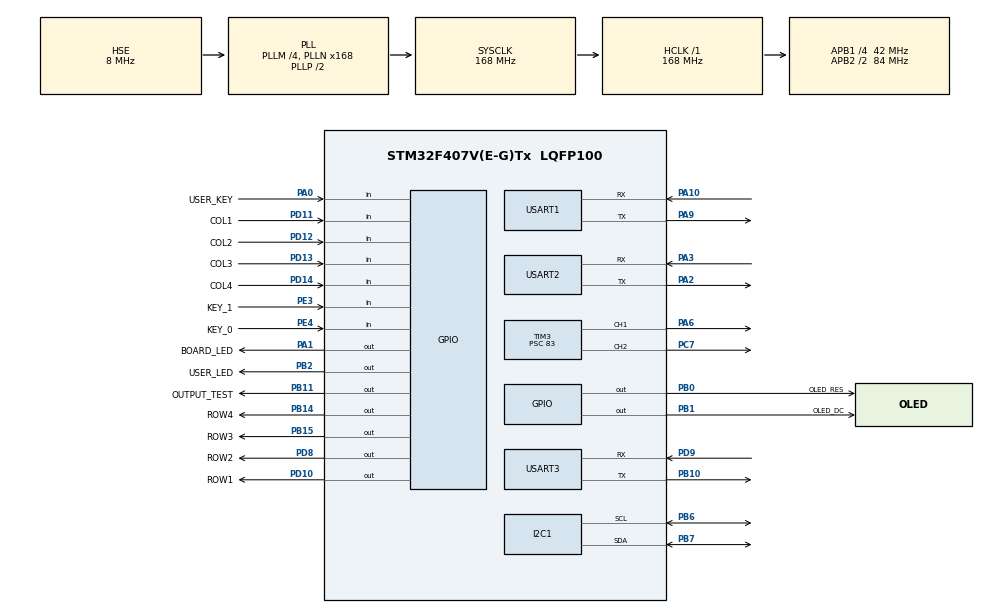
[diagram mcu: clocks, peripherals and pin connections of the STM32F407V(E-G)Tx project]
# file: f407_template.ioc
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Dma.Request0=USART2_RX
Dma.Request1=USART2_TX
Dma.Request2=USART1_RX
Dma.Request3=USART1_TX
Dma.USART1_RX.2.Direction=DMA_PERIPH_TO_MEMORY
Dma.USART1_RX.2.FIFOMode=DMA_FIFOMODE_DISABLE
Dma.USART1_RX.2.Instance=DMA2_Stream2
Dma.USART1_RX.2.MemDataAlignment=DMA_MDATAALIGN_BYTE
Dma.USART1_RX.2.MemInc=DMA_MINC_ENABLE
Dma.USART1_RX.2.Mode=DMA_NORMAL
Dma.USART1_RX.2.PeriphDataAlignment=DMA_PDATAALIGN_BYTE
Dma.USART1_RX.2.PeriphInc=DMA_PINC_DISABLE
Dma.USART1_RX.2.Priority=DMA_PRIORITY_LOW
Dma.USART1_TX.3.Direction=DMA_MEMORY_TO_PERIPH
Dma.USART1_TX.3.FIFOMode=DMA_FIFOMODE_DISABLE
Dma.USART1_TX.3.Instance=DMA2_Stream7
Dma.USART1_TX.3.MemDataAlignment=DMA_MDATAALIGN_BYTE
Dma.USART1_TX.3.MemInc=DMA_MINC_ENABLE
Dma.USART1_TX.3.Mode=DMA_NORMAL
Dma.USART1_TX.3.PeriphDataAlignment=DMA_PDATAALIGN_BYTE
Dma.USART1_TX.3.PeriphInc=DMA_PINC_DISABLE
Dma.USART1_TX.3.Priority=DMA_PRIORITY_LOW
Dma.USART2_RX.0.Direction=DMA_PERIPH_TO_MEMORY
Dma.USART2_RX.0.FIFOMode=DMA_FIFOMODE_DISABLE
Dma.USART2_RX.0.Instance=DMA1_Stream5
Dma.USART2_RX.0.MemDataAlignment=DMA_MDATAALIGN_BYTE
Dma.USART2_RX.0.MemInc=DMA_MINC_ENABLE
Dma.USART2_RX.0.Mode=DMA_NORMAL
Dma.USART2_RX.0.PeriphDataAlignment=DMA_PDATAALIGN_BYTE
Dma.USART2_RX.0.PeriphInc=DMA_PINC_DISABLE
Dma.USART2_RX.0.Priority=DMA_PRIORITY_MEDIUM
Dma.USART2_TX.1.Direction=DMA_MEMORY_TO_PERIPH
Dma.USART2_TX.1.FIFOMode=DMA_FIFOMODE_DISABLE
Dma.USART2_TX.1.Instance=DMA1_Stream6
Dma.USART2_TX.1.MemDataAlignment=DMA_MDATAALIGN_BYTE
Dma.USART2_TX.1.MemInc=DMA_MINC_ENABLE
Dma.USART2_TX.1.Mode=DMA_NORMAL
Dma.USART2_TX.1.PeriphDataAlignment=DMA_PDATAALIGN_BYTE
Dma.USART2_TX.1.PeriphInc=DMA_PINC_DISABLE
Dma.USART2_TX.1.Priority=DMA_PRIORITY_MEDIUM
I2C1.I2C_Mode=I2C_Standard
Mcu.Family=STM32F4
Mcu.Name=STM32F407V(E-G)Tx
Mcu.Package=LQFP100
NVIC.DMA1_Stream5_IRQn=true\:0\:0\:false\:false\:true\:false\:true\:true
NVIC.DMA1_Stream6_IRQn=true\:0\:0\:false\:false\:true\:false\:true\:true
NVIC.DMA2_Stream2_IRQn=true\:0\:0\:false\:false\:true\:false\:true\:true
NVIC.DMA2_Stream7_IRQn=true\:0\:0\:false\:false\:true\:false\:true\:true
NVIC.PriorityGroup=NVIC_PRIORITYGROUP_4
NVIC.TIM6_DAC_IRQn=true\:0\:0\:false\:false\:true\:true\:true\:true
NVIC.USART1_IRQn=true\:0\:0\:false\:false\:true\:true\:true\:true
NVIC.USART2_IRQn=true\:0\:0\:false\:false\:true\:true\:true\:true
PA0-WKUP.GPIO_Label=USER_KEY
PA0-WKUP.GPIO_PuPd=GPIO_PULLDOWN
PA0-WKUP.Signal=GPIO_Input
PA1.GPIO_Label=BOARD_LED
PA1.PinState=GPIO_PIN_RESET
PA1.Signal=GPIO_Output
PA10.Mode=Asynchronous
PA10.Signal=USART1_RX
PA13.Mode=Serial_Wire
PA13.Signal=SYS_JTMS-SWDIO
PA14.Mode=Serial_Wire
PA14.Signal=SYS_JTCK-SWCLK
PA2.Mode=Asynchronous
PA2.Signal=USART2_TX
PA3.Mode=Asynchronous
PA3.Signal=USART2_RX
PA6.Signal=S_TIM3_CH1
PA9.Mode=Asynchronous
PA9.Signal=USART1_TX
PB0.GPIO_Label=OLED_RES
PB0.Signal=GPIO_Output
PB1.GPIO_Label=OLED_DC
PB1.Signal=GPIO_Output
PB10.Mode=Asynchronous
PB10.Signal=USART3_TX
PB11.GPIO_Label=OUTPUT_TEST
PB11.GPIO_Speed=GPIO_SPEED_FREQ_HIGH
PB11.Signal=GPIO_Output
PB14.GPIO_Label=ROW4
PB14.GPIO_Speed=GPIO_SPEED_FREQ_HIGH
PB14.PinState=GPIO_PIN_SET
PB14.Signal=GPIO_Output
PB15.GPIO_Label=ROW3
PB15.GPIO_Speed=GPIO_SPEED_FREQ_HIGH
PB15.PinState=GPIO_PIN_SET
PB15.Signal=GPIO_Output
PB2.GPIO_Label=USER_LED
PB2.GPIO_Speed=GPIO_SPEED_FREQ_HIGH
PB2.Signal=GPIO_Output
PB6.Mode=I2C
PB6.Signal=I2C1_SCL
PB7.Mode=I2C
PB7.Signal=I2C1_SDA
PC14-OSC32_IN.Mode=LSE-External-Oscillator
PC14-OSC32_IN.Signal=RCC_OSC32_IN
PC15-OSC32_OUT.Mode=LSE-External-Oscillator
PC15-OSC32_OUT.Signal=RCC_OSC32_OUT
PC7.Signal=S_TIM3_CH2
PD10.GPIO_Label=ROW1
PD10.GPIO_Speed=GPIO_SPEED_FREQ_HIGH
PD10.PinState=GPIO_PIN_SET
PD10.Signal=GPIO_Output
PD11.GPIO_Label=COL1
PD11.GPIO_PuPd=GPIO_PULLUP
PD11.Signal=GPIO_Input
PD12.GPIO_Label=COL2
PD12.GPIO_PuPd=GPIO_PULLUP
PD12.Signal=GPIO_Input
PD13.GPIO_Label=COL3
PD13.GPIO_PuPd=GPIO_PULLUP
PD13.Signal=GPIO_Input
PD14.GPIO_Label=COL4
PD14.GPIO_PuPd=GPIO_PULLUP
PD14.Signal=GPIO_Input
PD8.GPIO_Label=ROW2
PD8.GPIO_Speed=GPIO_SPEED_FREQ_HIGH
PD8.PinState=GPIO_PIN_SET
PD8.Signal=GPIO_Output
PD9.Mode=Asynchronous
PD9.Signal=USART3_RX
PE3.GPIO_Label=KEY_1
PE3.GPIO_PuPd=GPIO_PULLUP
PE3.Signal=GPIO_Input
PE4.GPIO_Label=KEY_0
PE4.GPIO_PuPd=GPIO_PULLUP
PE4.Signal=GPIO_Input
PH0-OSC_IN.Mode=HSE-External-Oscillator
PH0-OSC_IN.Signal=RCC_OSC_IN
PH1-OSC_OUT.Mode=HSE-External-Oscillator
PH1-OSC_OUT.Signal=RCC_OSC_OUT
ProjectManager.HeapSize=0x200
ProjectManager.StackSize=0x400
ProjectManager.TargetToolchain=MDK-ARM V5.32
RCC.48MHZClocksFreq_Value=84000000
RCC.AHBFreq_Value=168000000
RCC.APB1CLKDivider=RCC_HCLK_DIV4
RCC.APB1Freq_Value=42000000
RCC.APB1TimFreq_Value=84000000
RCC.APB2CLKDivider=RCC_HCLK_DIV2
RCC.APB2Freq_Value=84000000
RCC.APB2TimFreq_Value=168000000
RCC.CortexFreq_Value=168000000
RCC.HCLKFreq_Value=168000000
RCC.HSE_VALUE=8000000
RCC.HSI_VALUE=16000000
RCC.PLLM=4
RCC.PLLN=168
RCC.PLLSourceVirtual=RCC_PLLSOURCE_HSE
RCC.SYSCLKFreq_VALUE=168000000
RCC.SYSCLKSource=RCC_SYSCLKSOURCE_PLLCLK
RCC.VCOOutputFreq_Value=336000000
SH.S_TIM3_CH1.0=TIM3_CH1,PWM Generation1 CH1
SH.S_TIM3_CH2.0=TIM3_CH2,PWM Generation2 CH2
TIM3.AutoReloadPreload=TIM_AUTORELOAD_PRELOAD_ENABLE
TIM3.Channel-PWM\ Generation1\ CH1=TIM_CHANNEL_1
TIM3.Channel-PWM\ Generation2\ CH2=TIM_CHANNEL_2
TIM3.Period=20000-1
TIM3.Prescaler=83
TIM6.AutoReloadPreload=TIM_AUTORELOAD_PRELOAD_ENABLE
TIM6.Period=19999
TIM6.Prescaler=83
USART1.VirtualMode=VM_ASYNC
USART2.VirtualMode=VM_ASYNC
USART3.VirtualMode=VM_ASYNC
VP_TIM6_VS_ClockSourceINT.Mode=Enable_Timer
board=custom

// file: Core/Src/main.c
/* USER CODE BEGIN Header */
/**
  ******************************************************************************
  * @file           : main.c
  * @brief          : Main program body
  ******************************************************************************
  * @attention
  *
  * Copyright (c) 2025 STMicroelectronics.
  * All rights reserved.
  *
  * This software is licensed under terms that can be found in the LICENSE file
  * in the root directory of this software component.
  * If no LICENSE file comes with this software, it is provided AS-IS.
  *
  ******************************************************************************
  */
/* USER CODE END Header */
#include "main.h"
#include "dma.h"
#include "i2c.h"
#include "tim.h"
#include "usart.h"
#include "gpio.h"

/* USER CODE BEGIN Includes */
#include "user_init.h"
#include "task_scheduler.h"
/* USER CODE END Includes */

void SystemClock_Config(void);

int main(void)
{

  /* MCU Configuration--------------------------------------------------------*/

  /* Reset of all peripherals, Initializes the Flash interface and the Systick. */
 HAL_Init();

  /* Configure the system clock */
  SystemClock_Config();

  /* Initialize all configured peripherals */
  MX_GPIO_Init();
  MX_DMA_Init();
  MX_TIM3_Init();
  MX_TIM6_Init();
  MX_USART2_UART_Init();
  MX_I2C1_Init();
  MX_USART1_UART_Init();
  MX_USART3_UART_Init();
  /* USER CODE BEGIN 2 */
  User_Init();
  /* USER CODE END 2 */

  /* Infinite loop */
  while (1)
  {

    /* USER CODE BEGIN 3 */
    TaskScheduler_Run();
  }
  /* USER CODE END 3 */
}

void SystemClock_Config(void)
{
  RCC_OscInitTypeDef RCC_OscInitStruct = {0};
  RCC_ClkInitTypeDef RCC_ClkInitStruct = {0};

  /** Configure the main internal regulator output voltage
  */
  __HAL_RCC_PWR_CLK_ENABLE();
  __HAL_PWR_VOLTAGESCALING_CONFIG(PWR_REGULATOR_VOLTAGE_SCALE1);

  /** Initializes the RCC Oscillators according to the specified parameters
  * in the RCC_OscInitTypeDef structure.
  */
  RCC_OscInitStruct.OscillatorType = RCC_OSCILLATORTYPE_HSE;
  RCC_OscInitStruct.HSEState = RCC_HSE_ON;
  RCC_OscInitStruct.PLL.PLLState = RCC_PLL_ON;
  RCC_OscInitStruct.PLL.PLLSource = RCC_PLLSOURCE_HSE;
  RCC_OscInitStruct.PLL.PLLM = 4;
  RCC_OscInitStruct.PLL.PLLN = 168;
  RCC_OscInitStruct.PLL.PLLP = RCC_PLLP_DIV2;
  RCC_OscInitStruct.PLL.PLLQ = 4;
  if (HAL_RCC_OscConfig(&RCC_OscInitStruct) != HAL_OK)
  {
    Error_Handler();
  }

  /** Initializes the CPU, AHB and APB buses clocks
  */
  RCC_ClkInitStruct.ClockType = RCC_CLOCKTYPE_HCLK|RCC_CLOCKTYPE_SYSCLK
                              |RCC_CLOCKTYPE_PCLK1|RCC_CLOCKTYPE_PCLK2;
  RCC_ClkInitStruct.SYSCLKSource = RCC_SYSCLKSOURCE_PLLCLK;
  RCC_ClkInitStruct.AHBCLKDivider = RCC_SYSCLK_DIV1;
  RCC_ClkInitStruct.APB1CLKDivider = RCC_HCLK_DIV4;
  RCC_ClkInitStruct.APB2CLKDivider = RCC_HCLK_DIV2;

  if (HAL_RCC_ClockConfig(&RCC_ClkInitStruct, FLASH_LATENCY_5) != HAL_OK)
  {
    Error_Handler();
  }
}

void Error_Handler(void)
{
  __disable_irq();
  while (1)
  {
  }
}
